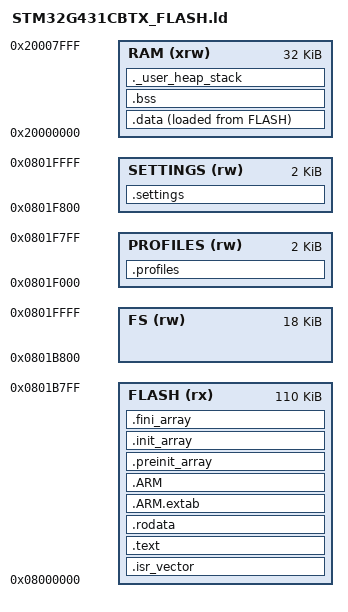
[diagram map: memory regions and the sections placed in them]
/*
******************************************************************************
**
** @file        : LinkerScript.ld
**
** @author      : Auto-generated by STM32CubeIDE
**
** @brief       : Linker script for STM32G431CBTx Device from STM32G4 series
**                      128KBytes FLASH
**                      32KBytes RAM
**
**                Set heap size, stack size and stack location according
**                to application requirements.
**
**                Set memory bank area and size if external memory is used
**
**  Target      : STMicroelectronics STM32
**
**  Distribution: The file is distributed as is, without any warranty
**                of any kind.
**
******************************************************************************
** @attention
**
** Copyright (c) 2024 STMicroelectronics.
** All rights reserved.
**
** This software is licensed under terms that can be found in the LICENSE file
** in the root directory of this software component.
** If no LICENSE file comes with this software, it is provided AS-IS.
**
******************************************************************************
*/

/* Entry Point */
ENTRY(Reset_Handler)

/* Highest address of the user mode stack */
_estack = ORIGIN(RAM) + LENGTH(RAM); /* end of "RAM" Ram type memory */

_Min_Heap_Size = 0x200; /* required amount of heap */
_Min_Stack_Size = 0x400; /* required amount of stack */

/* Memories definition */
MEMORY
{
  RAM      (xrw)    : ORIGIN = 0x20000000,   LENGTH = 32K
  FLASH    (rx)     : ORIGIN = 0x8000000,    LENGTH = 110K
  FS       (rw)     : ORIGIN = 0x0801B800,   LENGTH = 18K
  PROFILES (rw)     : ORIGIN = 0x0801F000,   LENGTH = 2K
  SETTINGS (rw)     : ORIGIN = 0x0801F800,   LENGTH = 2K
}

/* FAT volume used by the USB-storage (USB MSC) mode.
 * 20 KB = 40 sectors x 512 B; with 512-byte clusters, 1 FAT and a 16-entry
 * root directory that leaves 37 clusters - FatFS refuses FAT12 volumes with
 * fewer than 33 clusters (MIN_FAT12), so this is the smallest legal size.
 * The size is a multiple of the 2 KB flash page, so page rewrites stay inside
 * the region. Not a C section: only the address is exposed to fs_disk.c. */
_sfs = ORIGIN(FS);
_efs = ORIGIN(FS) + LENGTH(FS);

/* Sections */
SECTIONS
{
  /* The startup code into "FLASH" Rom type memory */
  .isr_vector :
  {
    . = ALIGN(4);
    KEEP(*(.isr_vector)) /* Startup code */
    . = ALIGN(4);
  } >FLASH

  /* The program code and other data into "FLASH" Rom type memory */
  .text :
  {
    . = ALIGN(4);
    *(.text)           /* .text sections (code) */
    *(.text*)          /* .text* sections (code) */
    *(.glue_7)         /* glue arm to thumb code */
    *(.glue_7t)        /* glue thumb to arm code */
    *(.eh_frame)

    KEEP (*(.init))
    KEEP (*(.fini))

    . = ALIGN(4);
    _etext = .;        /* define a global symbols at end of code */
  } >FLASH

  /* Constant data into "FLASH" Rom type memory */
  .rodata :
  {
    . = ALIGN(4);
    *(.rodata)         /* .rodata sections (constants, strings, etc.) */
    *(.rodata*)        /* .rodata* sections (constants, strings, etc.) */
    . = ALIGN(4);
  } >FLASH

  .ARM.extab (READONLY)  : {
    . = ALIGN(4);
    *(.ARM.extab* .gnu.linkonce.armextab.*)
    . = ALIGN(4);
  } >FLASH

  .ARM (READONLY) : {
    . = ALIGN(4);
    __exidx_start = .;
    *(.ARM.exidx*)
    __exidx_end = .;
    . = ALIGN(4);
  } >FLASH

  .preinit_array (READONLY)    :
  {
    . = ALIGN(4);
    PROVIDE_HIDDEN (__preinit_array_start = .);
    KEEP (*(.preinit_array*))
    PROVIDE_HIDDEN (__preinit_array_end = .);
    . = ALIGN(4);
  } >FLASH

  .init_array (READONLY) :
  {
    . = ALIGN(4);
    PROVIDE_HIDDEN (__init_array_start = .);
    KEEP (*(SORT(.init_array.*)))
    KEEP (*(.init_array*))
    PROVIDE_HIDDEN (__init_array_end = .);
    . = ALIGN(4);
  } >FLASH

  .fini_array (READONLY) :
  {
    . = ALIGN(4);
    PROVIDE_HIDDEN (__fini_array_start = .);
    KEEP (*(SORT(.fini_array.*)))
    KEEP (*(.fini_array*))
    PROVIDE_HIDDEN (__fini_array_end = .);
    . = ALIGN(4);
  } >FLASH

  /* Used by the startup to initialize data */
  _sidata = LOADADDR(.data);

  /* Initialized data sections into "RAM" Ram type memory */
  .data :
  {
    . = ALIGN(4);
    _sdata = .;        /* create a global symbol at data start */
    *(.data)           /* .data sections */
    *(.data*)          /* .data* sections */
    *(.RamFunc)        /* .RamFunc sections */
    *(.RamFunc*)       /* .RamFunc* sections */

    . = ALIGN(4);
    _edata = .;        /* define a global symbol at data end */

  } >RAM AT> FLASH

  /* Uninitialized data section into "RAM" Ram type memory */
  . = ALIGN(4);
  .bss :
  {
    /* This is used by the startup in order to initialize the .bss section */
    _sbss = .;         /* define a global symbol at bss start */
    __bss_start__ = _sbss;
    *(.bss)
    *(.bss*)
    *(COMMON)

    . = ALIGN(4);
    _ebss = .;         /* define a global symbol at bss end */
    __bss_end__ = _ebss;
  } >RAM

  /* User_heap_stack section, used to check that there is enough "RAM" Ram  type memory left */
  ._user_heap_stack :
  {
    . = ALIGN(8);
    PROVIDE ( end = . );
    PROVIDE ( _end = . );
    . = . + _Min_Heap_Size;
    . = . + _Min_Stack_Size;
    . = ALIGN(8);
  } >RAM

  /* Profiles data in dedicated flash page */
  .profiles :
  {
    . = ALIGN(4);
    _sprofiles = .;
    KEEP(*(.profiles))
    KEEP(*(.profiles*))
    . = ALIGN(4);
    _eprofiles = .;
  } >PROFILES

  /* Settings data in dedicated flash page */
  .settings :
  {
    . = ALIGN(4);
    _ssettings = .;
    KEEP(*(.settings))
    KEEP(*(.settings*))
    . = ALIGN(4);
    _esettings = .;
  } >SETTINGS

  /* Remove information from the compiler libraries */
  /DISCARD/ :
  {
    libc.a ( * )
    libm.a ( * )
    libgcc.a ( * )
  }

  .ARM.attributes 0 : { *(.ARM.attributes) }
}
